# COMPUTE_CLUSTER0_SS_CFG register map
Vendor: Texas Instruments
Peripheral module from a debugger description file (folder J7VCL).
Registers are 32-bit, access per field, reset 0x0 unless marked. A register's access mark holds for its fields unless they carry their own. Offsets are as the file gives them; lines under a group give offsets from that group; [hi:lo] are bit positions; {n}, {i} and the like mark numbered series; 'fields as' and 'values as' point back to an identical list; <NAME> marks a mode.

## COMPUTE_CLUSTER0_SS_CFG
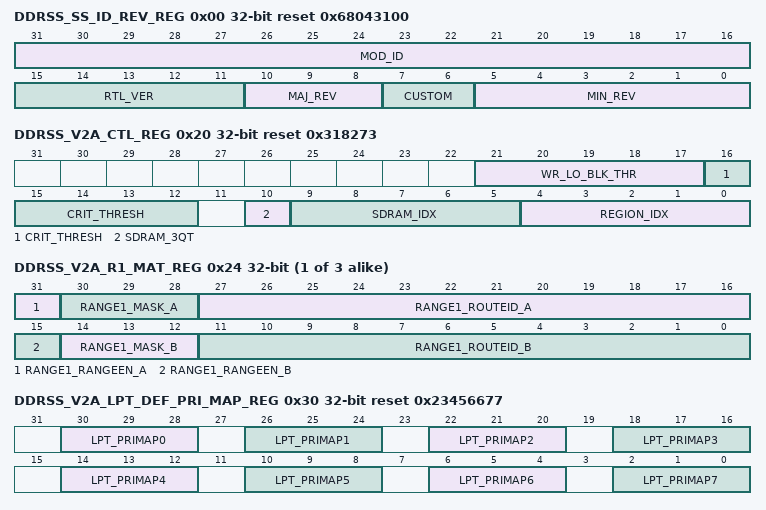
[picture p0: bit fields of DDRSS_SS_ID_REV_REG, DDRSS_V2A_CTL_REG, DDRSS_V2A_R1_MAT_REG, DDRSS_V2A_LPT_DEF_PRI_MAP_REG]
0x00 DDRSS_SS_ID_REV_REG ro reset 0x68043100 — Return to the . The Subsystem ID and Revision Register contains the module ID, major, and minor revisions for the subsystem.
  [31:16] MOD_ID — Module ID
  [15:11] RTL_VER — RTL version
  [10:8] MAJ_REV — Major revision
  [7:6] CUSTOM
  [5:0] MIN_REV — Minor revision
0x04 DDRSS_SS_CTL_REG — Return to the . The Subsystem Control Register contains fields for control functions required for submodules in the subsystem.
  [0] PHY_PLL_BYPASS rw — DDR PHY De-Skew PLL bypass.Write 1 to bypass PLL.
0x20 DDRSS_V2A_CTL_REG reset 0x318273 — Return to the . The MSMC2DDR Bridge Control register contains control functions required for the MSMC2DDR Bridge submodule.
  [21:17] WR_LO_BLK_THR rw — Write data threshold in 64 byte quantas.The MSMC2DDR bridge will block all Low Priority Thread writes to DDR when the total number of write data bytes sent to the DDR controller is greater than this value. The reset value of this field is optimal however, it can be changed for better traffic shaping.
  [16:12] CRIT_THRESH rw — Critical threshold.The MSMC2DDR bridge will block all Low Priority Thread traffic to DDR when the total number of commands sent to the DDR controller is greater than this value. The reset value of this field is optimal however, it can be changed for better traffic shaping.
  [10] SDRAM_3QT rw — Setting this field to a 1 will modify SDRAM Index to be 3/4 its programmed value to support 3, 6, 12 and 24 GB sizes.
  [9:5] SDRAM_IDX rw — SDRAM Index = log2(connected SDRAM size) - 16.The sdram_idx describes the number of address bits minus 16 that are used to determine the mask used to detect memory rollover and prevent aliasing and false coherency issues. Max size supported is 32GB. A programmed value greater than 0x13 will result in this field being reset to 0x13.
  [4:0] REGION_IDX rw — Region Index = log2(CBA region size) - 16.The region_idx describes the number of address bits minus 16 that are used to determine the mask used to detect memory rollover and prevent aliasing and false coherency issues. Max size supported is 32GB. A programmed value greater than 0x13 will result in this field being reset to 0x13.
{0x20+4i} DDRSS_V2A_R{i}_MAT_REG rw (i=1..3) — Return to the . The Range {i} Match Register allows a single master to a range of masters to change their priority mapping. This allows selective masters to be increased or decreased in effective priority. Range {i} Match Register uses the associated Range {i} Priority Map Register. The highest Range Match Register will take priority and will be used in case of multiple range matches.
  [31] RANGE{i}_RANGEEN_A — The range{i}_rangeen_a enables the RouteID AND'd with range{i}_mask_a to match the range{i}_routeid_a
  [30:28] RANGE{i}_MASK_A — The range{i}_mask_a allows a number of least significant bits to be ignored prior to the match of the routeid_a
  [27:16] RANGE{i}_ROUTEID_A — The range{i}_routeid_a is the value that is compared to the RouteID arriving on the command interface
  [15] RANGE{i}_RANGEEN_B — The range{i}_rangeen_b enables the RouteID AND'd with range{i}_mask_b to match the range{i}_routeid_b
  [14:12] RANGE{i}_MASK_B — The range{i}_mask_b allows a number of least significant bits to be ignored prior to the match of the routeid_b
  [11:0] RANGE{i}_ROUTEID_B — The range{i}_routeid_b is the value that is compared to the RouteID arriving on the command interface
0x30 DDRSS_V2A_LPT_DEF_PRI_MAP_REG reset 0x23456677 — Return to the . The LPT Default Priority Mapping Register is the default map for the inbound VBUSM.C priority on the Low Priority Thread to AXI priority.
  [30:28] LPT_PRIMAP0 rw — The field contains AXI priority value for VBUSM.C priority 0.0=highest priority. 7=lowest priority
  [26:24] LPT_PRIMAP1 rw — The field contains AXI priority value for VBUSM.C priority 1.0=highest priority. 7=lowest priority
  [22:20] LPT_PRIMAP2 rw — The field contains AXI priority value for VBUSM.C priority 2.0=highest priority. 7=lowest priority
  [18:16] LPT_PRIMAP3 rw — The field contains AXI priority value for VBUSM.C priority 3.0=highest priority. 7=lowest priority
  [14:12] LPT_PRIMAP4 rw — The field contains AXI priority value for VBUSM.C priority 4.0=highest priority. 7=lowest priority
  [10:8] LPT_PRIMAP5 rw — The field contains AXI priority value for VBUSM.C priority 5.0=highest priority. 7=lowest priority
  [6:4] LPT_PRIMAP6 rw — The field contains AXI priority value for VBUSM.C priority 6.0=highest priority. 7=lowest priority
  [2:0] LPT_PRIMAP7 rw — The field contains AXI priority value for VBUSM.C priority 7.0=highest priority. 7=lowest priority
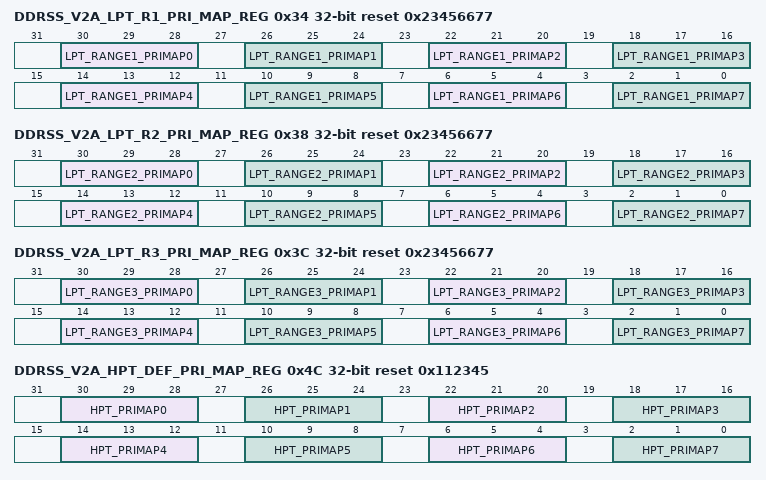
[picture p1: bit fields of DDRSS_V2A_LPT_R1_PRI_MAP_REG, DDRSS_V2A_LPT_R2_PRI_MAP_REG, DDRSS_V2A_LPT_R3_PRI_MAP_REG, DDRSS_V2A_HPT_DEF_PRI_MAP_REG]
0x34 DDRSS_V2A_LPT_R1_PRI_MAP_REG reset 0x23456677 — Return to the . The LPT Range 1 Priority Mapping Register is used to map the inbound VBUSM.C priority on the Low Priority Thread to AXI priority when a RouteID match 1 occurs. This allows the priority level to be changed from the LPT Default Priority Mapping value.
  [30-4n:28-4n] LPT_RANGE1_PRIMAP{n} rw (n=0..7) — The field contains AXI priority value for VBUSM.C priority {n} for range match 1.0=highest priority. 7=lowest priority
0x38 DDRSS_V2A_LPT_R2_PRI_MAP_REG reset 0x23456677 — Return to the . The LPT Range 2 Priority Mapping Register is used to map the inbound VBUSM.C priority on the Low Priority Thread to AXI priority when a RouteID match 2 occurs. This allows the priority level to be changed from the LPT Default Priority Mapping value.
  [30-4n:28-4n] LPT_RANGE2_PRIMAP{n} rw (n=0..7) — The field contains AXI priority value for VBUSM.C priority {n} for range match 2.0=highest priority. 7=lowest priority
0x3C DDRSS_V2A_LPT_R3_PRI_MAP_REG reset 0x23456677 — Return to the . The LPT Range 3 Priority Mapping Register is used to map the inbound VBUSM.C priority on the Low Priority Thread to AXI priority when a RouteID match 3 occurs. This allows the priority level to be changed from the LPT Default Priority Mapping value.
  [30-4n:28-4n] LPT_RANGE3_PRIMAP{n} rw (n=0..7) — The field contains AXI priority value for VBUSM.C priority {n} for range match 3.0=highest priority. 7=lowest priority
0x4C DDRSS_V2A_HPT_DEF_PRI_MAP_REG reset 0x112345 — Return to the . The HPT Default Priority Mapping Register is the default map for the inbound VBUSM.C priority on the High Priority Thread to the AXI priority.
  [30:28] HPT_PRIMAP0 rw — The field contains AXI priority value for VBUSM.C priority 0.0=highest priority. 7=lowest priority
  [26:24] HPT_PRIMAP1 rw — The field contains AXI priority value for VBUSM.C priority 1.0=highest priority. 7=lowest priority
  [22:20] HPT_PRIMAP2 rw — The field contains AXI priority value for VBUSM.C priority 2.0=highest priority. 7=lowest priority
  [18:16] HPT_PRIMAP3 rw — The field contains AXI priority value for VBUSM.C priority 3.0=highest priority. 7=lowest priority
  [14:12] HPT_PRIMAP4 rw — The field contains AXI priority value for VBUSM.C priority 4.0=highest priority. 7=lowest priority
  [10:8] HPT_PRIMAP5 rw — The field contains AXI priority value for VBUSM.C priority 5.0=highest priority. 7=lowest priority
  [6:4] HPT_PRIMAP6 rw — The field contains AXI priority value for VBUSM.C priority 6.0=highest priority. 7=lowest priority
  [2:0] HPT_PRIMAP7 rw — The field contains AXI priority value for VBUSM.C priority 7.0=highest priority. 7=lowest priority
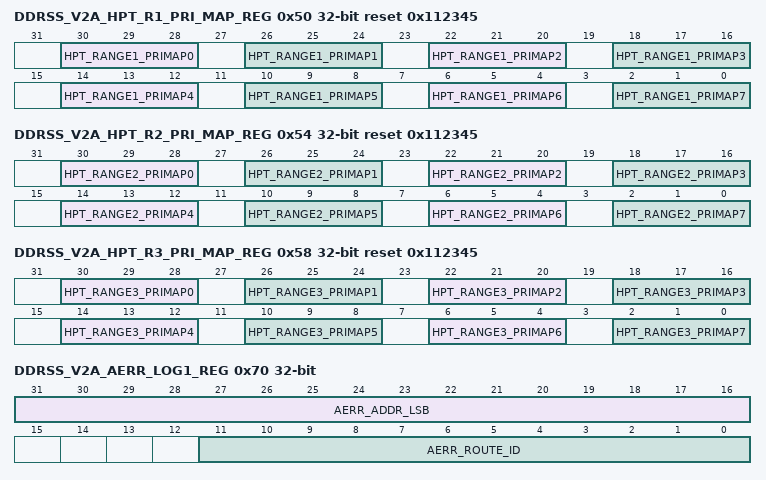
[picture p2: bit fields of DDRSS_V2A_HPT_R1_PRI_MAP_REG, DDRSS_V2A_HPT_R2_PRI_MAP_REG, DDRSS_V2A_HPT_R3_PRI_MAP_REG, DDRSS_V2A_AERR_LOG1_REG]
0x50 DDRSS_V2A_HPT_R1_PRI_MAP_REG reset 0x112345 — Return to the . The HPT Range 1 Priority Mapping Register is used to map the inbound VBUSM.C priority on the High Priority Thread to AXI priority when a RouteID match 1 occurs. This allows the priority level to be changed from the HPT Default Priority Mapping value.
  [30-4n:28-4n] HPT_RANGE1_PRIMAP{n} rw (n=0..7) — The field contains AXI priority value for VBUSM.C priority {n} for range match 1.0=highest priority. 7=lowest priority
0x54 DDRSS_V2A_HPT_R2_PRI_MAP_REG reset 0x112345 — Return to the . The HPT Range 2 Priority Mapping Register is used to map the inbound VBUSM.C priority on the High Priority Thread to AXI priority when a RouteID match 2 occurs. This allows the priority level to be changed from the HPT Default Priority Mapping value.
  [30-4n:28-4n] HPT_RANGE2_PRIMAP{n} rw (n=0..7) — The field contains AXI priority value for VBUSM.C priority {n} for range match 2.0=highest priority. 7=lowest priority
0x58 DDRSS_V2A_HPT_R3_PRI_MAP_REG reset 0x112345 — Return to the . The HPT Range 3 Priority Mapping Register is used to map the inbound VBUSM.C priority on the High Priority Thread to AXI priority when a RouteID match 3 occurs. This allows the priority level to be changed from the HPT Default Priority Mapping value.
  [30-4n:28-4n] HPT_RANGE3_PRIMAP{n} rw (n=0..7) — The field contains AXI priority value for VBUSM.C priority {n} for range match 3.0=highest priority. 7=lowest priority
0x70 DDRSS_V2A_AERR_LOG1_REG access not given — Return to the . The Address Error Log 1 register displays the RouteID and lsb of the address for the first VBUSM.C command that was outside the programmed addressing range. Writing a 0x1 will clear all fields. Writing any other value has no effect. The Address Error Log 2 register will also be cleared upon writing this register.
  [31:16] AERR_ADDR_LSB — Address[15:0] of the VBUSM.C command (access RW1C)
  [11:0] AERR_ROUTE_ID — RouteID of the VBUSM.C write command (access RW1C)
0x74 DDRSS_V2A_AERR_LOG2_REG ro — Return to the . The Address Error Log 2 registers displays the msb of the address for the first VBUSM.C command that was outside the programmed addressing range. This register will be cleared upon writing the Address Error Log 1 register.
  [31:0] AERR_ADDR_MSB — Address[34:16] of the VBUSM.C command
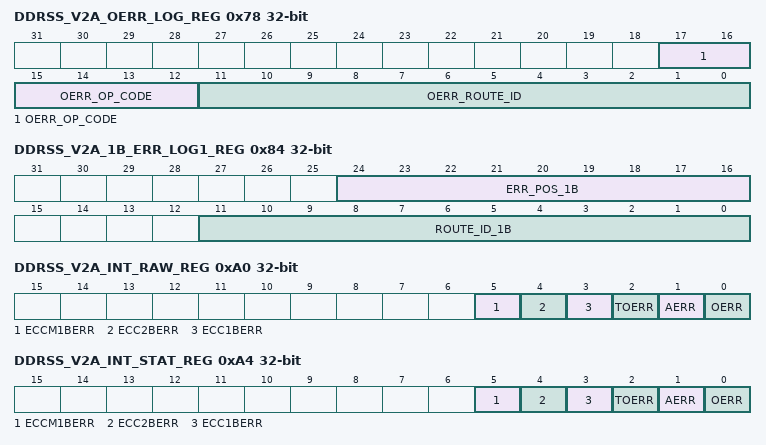
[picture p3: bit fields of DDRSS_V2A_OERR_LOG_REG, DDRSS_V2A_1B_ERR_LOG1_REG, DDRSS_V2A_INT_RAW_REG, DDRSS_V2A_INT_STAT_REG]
0x78 DDRSS_V2A_OERR_LOG_REG access not given — Return to the . The Opcode Error Log register displays the RouteID and opcode for the first VBUSM.C command that had an unsupported opcode. Writing a 0x1 will clear all fields. Writing any other value has no effect.
  [17:12] OERR_OP_CODE — Opcode of the VBUSM.C command (access RW1C)
  [11:0] OERR_ROUTE_ID — RouteID of the VBUSM.C command (access RW1C)
0x80 DDRSS_V2A_1B_ERR_CNT_REG access not given — Return to the . MSMC2DDR Bridge 1-Bit EDC Error Count Register
  [15:0] EDC_1B_ERR_CNT — 16-bit counter that displays number of 1-bit EDC errors on write data received on the VBUSM.C interface. Writing a 0x1 will clear this count. Writing any other value has no effect. (access RW1C)
0x84 DDRSS_V2A_1B_ERR_LOG1_REG access not given — Return to the . The 1-Bit EDC Error Log 1 register displays the RouteID and error position of the first VBUSM.C write that incurred 1-bit EDC error. Writing a 0x1 will clear all fields. Writing any other value has no effect. The 1-Bit EDC Error Log 2 register will also be cleared upon writing this register.
  [24:16] ERR_POS_1B — Bit error position (access RW1C)
  [11:0] ROUTE_ID_1B — RouteID of the VBUSM.C write command (access RW1C)
0x88 DDRSS_V2A_1B_ERR_LOG2_REG ro — Return to the . The 1-Bit EDC Error Log 2 registers displays the address of the first VBUSM.C write that incurred 1-bit EDC error. This register will be cleared upon writing the 1-Bit EDC Error Log 1 register.
  [29:0] ADDR_MSB_1B — Address[34:5] of the VBUSM.C write command
0x8C DDRSS_V2A_2B_ERR_LOG1_REG access not given — Return to the . The 2-Bit EDC Error Log 1 register displays the RouteID of the first VBUSM.C write that incurred 2-bit EDC error. Writing a 0x1 clear all fields. Writing any other value has no effect. The 2-Bit EDC Error Log 2 register will also be cleared upon writing this register.
  [11:0] ROUTE_ID_2B — RouteID of the VBUSM.C write command (access RW1C)
0x90 DDRSS_V2A_2B_ERR_LOG2_REG ro — Return to the . The 2-Bit EDC Error Log 1 register displays the address of the first VBUSM.C write that incurred 2-bit EDC error. This register will be cleared upon writing the 2-Bit EDC Error Log 1 register.
  [29:0] ADR_MSB_2B — Address[34:5] of the VBUSM.C write command
0x9C DDRSS_V2A_BUS_TO reset 0xFFFFFF — Return to the . MSMC2DDR Bridge Bus Timeout Register
  [23:0] BUS_TIMER rw — AXI bus timeout value.Number of DDR clock cycles after which the MSMC2DDR bridge times out if a hang on the controller AXI interface is detected. A value of N will be equal to N x 16 clocks. Writing a 0 will disable the timeout feature.
0xA0 DDRSS_V2A_INT_RAW_REG access not given — Return to the . MSMC2DDR Bridge Interrupt Raw Status Register
  [5] ECCM1BERR — Raw status of SDRAM ECC multi 1-bit errors in same SDRAM burst.Write 1 to set the (raw) status, mostly for debug. Writing a 0 has no effect. (access RW1S)
  [4] ECC2BERR — Raw status of SDRAM ECC 2-bit error.Write 1 to set the (raw) status, mostly for debug. Writing a 0 has no effect. (access RW1S)
  [3] ECC1BERR — Raw status of SDRAM ECC 1-bit error.Write 1 to set the (raw) status, mostly for debug. Writing a 0 has no effect. (access RW1S)
  [2] TOERR — Raw status of MSMC2DDR Bridge interrupt for controller AXI interface timeout.Write 1 to set the (raw) status, mostly for debug. Writing a 0 has no effect. (access RW1S)
  [1] AERR — Raw status of MSMC2DDR Bridge interrupt for VBUSM.C address outside the programmed range.Write 1 to set the (raw) status, mostly for debug. Writing a 0 has no effect. (access RW1S)
  [0] OERR — Raw status of MSMC2DDR Bridge interrupt for VBUSM.C unsupported opcode.Write 1 to set the (raw) status, mostly for debug. Writing a 0 has no effect. (access RW1S)
0xA4 DDRSS_V2A_INT_STAT_REG access not given — Return to the . MSMC2DDR Bridge Interrupt Status Register
  [5] ECCM1BERR — Enabled status of SDRAM ECC multi 1-bit errors in same SDRAM burst.Write 1 to clear the status after interrupt has been serviced (raw status gets cleared, i.e. even if not enabled). Writing a 0 has no effect. (access RW1C)
  [4] ECC2BERR — Enabled status of SDRAM ECC 2-bit error.Write 1 to clear the status after interrupt has been serviced (raw status gets cleared, i.e. even if not enabled). Writing a 0 has no effect. (access RW1C)
  [3] ECC1BERR — Enabled status of SDRAM ECC 1-bit error.Write 1 to clear the status after interrupt has been serviced (raw status gets cleared, i.e. even if not enabled). Writing a 0 has no effect. (access RW1C)
  [2] TOERR — Enabled status of MSMC2DDR Bridge interrupt for controller AXI interface timeout.Write 1 to clear the status after interrupt has been serviced (raw status gets cleared, i.e. even if not enabled). Writing a 0 has no effect. (access RW1C)
  [1] AERR — Enabled status of MSMC2DDR Bridge interrupt for VBUSM.C address outside the programmed range.Write 1 to clear the status after interrupt has been serviced (raw status gets cleared, i.e. even if not enabled). Writing a 0 has no effect. (access RW1C)
  [0] OERR — Enabled status of MSMC2DDR Bridge interrupt for VBUSM.C unsupported opcode.Write 1 to clear the status after interrupt has been serviced (raw status gets cleared, i.e. even if not enabled). Writing a 0 has no effect. (access RW1C)
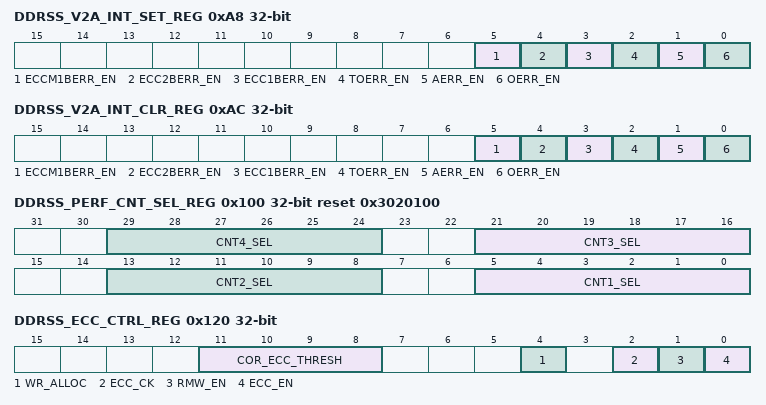
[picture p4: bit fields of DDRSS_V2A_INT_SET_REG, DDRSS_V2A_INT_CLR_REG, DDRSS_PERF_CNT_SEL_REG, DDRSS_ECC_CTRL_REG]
0xA8 DDRSS_V2A_INT_SET_REG access not given — Return to the . MSMC2DDR Bridge Interrupt Enable Set Register
  [5] ECCM1BERR_EN — Enable set for SDRAM ECC multi1-bit errors in same SDRAM burst. Writing a 1 will enable the interrupt, and set this bit as well as the corresponding Interrupt Enable Clear Register. Writing a 0 has no effect. (access RW1S)
  [4] ECC2BERR_EN — Enable set for SDRAM ECC2-bit error. Writing a 1 will enable the interrupt, and set this bit as well as the corresponding Interrupt Enable Clear Register. Writing a 0 has no effect. (access RW1S)
  [3] ECC1BERR_EN — Enable set for SDRAM ECC1-bit error. Writing a 1 will enable the interrupt, and set this bit as well as the corresponding Interrupt Enable Clear Register. Writing a 0 has no effect. (access RW1S)
  [2] TOERR_EN — Enable set for MSMC2DDR Bridge interrupt for controller AXI interface timeout.Writing a 1 will enable the interrupt, and set this bit as well as the corresponding Interrupt Enable Clear Register. Writing a 0 has no effect. (access RW1S)
  [1] AERR_EN — Enable set for MSMC2DDR Bridge interrupt for VBUSM.C address outside the programmed range.Writing a 1 will enable the interrupt, and set this bit as well as the corresponding Interrupt Enable Clear Register. Writing a 0 has no effect. (access RW1S)
  [0] OERR_EN — Enable set for MSMC2DDR Bridge interrupt for VBUSM.C unsupported opcode.Writing a 1 will enable the interrupt, and set this bit as well as the corresponding Interrupt Enable Clear Register. Writing a 0 has no effect. (access RW1S)
0xAC DDRSS_V2A_INT_CLR_REG access not given — Return to the . MSMC2DDR Bridge Interrupt Enable Clear Register
  [5] ECCM1BERR_EN — Enable clear for SDRAM ECC multi1-bit errors in same SDRAM burst. Writing a 1 will disable the interrupt, and clear this bit as well as the corresponding Interrupt Enable Set Register. Writing a 0 has no effect. (access RW1C)
  [4] ECC2BERR_EN — Enable clear for SDRAM ECC2-bit error. Writing a 1 will disable the interrupt, and clear this bit as well as the corresponding Interrupt Enable Set Register. Writing a 0 has no effect. (access RW1C)
  [3] ECC1BERR_EN — Enable clear for SDRAM ECC1-bit error. Writing a 1 will disable the interrupt, and clear this bit as well as the corresponding Interrupt Enable Set Register. Writing a 0 has no effect. (access RW1C)
  [2] TOERR_EN — Enable clear for MSMC2DDR Bridge interrupt for controller AXI interface timeout.Writing a 1 will disable the interrupt, and clear this bit as well as the corresponding Interrupt Enable Set Register. Writing a 0 has no effect. (access RW1C)
  [1] AERR_EN — Enable clear for MSMC2DDR Bridge interrupt for VBUSM.C address outside the programmed range.Writing a 1 will disable the interrupt, and clear this bit as well as the corresponding Interrupt Enable Set Register. Writing a 0 has no effect. (access RW1C)
  [0] OERR_EN — Enable clear for MSMC2DDR Bridge interrupt for VBUSM.C unsupported opcode.Writing a 1 will disable the interrupt, and clear this bit as well as the corresponding Interrupt Enable Set Register. Writing a 0 has no effect. (access RW1C)
0xB0 DDRSS_V2A_EOI_REG — Return to the . MSMC2DDR Bridge End of Interrupt Register
  [1:0] EOI wo — Software End Of Interrupt (EOI) control.Write 0 for aerr/oerr/toerr interrupt. Write 1 for ecc1b interrupt. Write 2 for ecc2b interrupt. This field always reads 0 (no EOI memory).
0x100 DDRSS_PERF_CNT_SEL_REG reset 0x3020100 — Return to the . The Performance Counter Select register is used to select the statistic type to be counted in the corresponding Performance Counter register.
  [8n-3:8n-8] CNT{n}_SEL rw (n=1..4) — Statistic select for Performance Counter {n} register. 0x0 = Counts every Write command. 0x1 = Counts every Read command. 0x2 = Counts every read as a result of a RMW command. 0x3 = Counts every Activate command. 0x4 = Counts every Precharge command. 0x5 = Counts every Precharge All command. 0x6 = Counts every Mode Register Read command. 0x7 = Counts every Mode Register Write command. 0x8 = Counts every Per Bank Refresh command. 0x9 = Counts every Auto Refresh command. 0xA = Counts every ZQ Calib Long command. 0xB = Counts every ZQ Calib Short command. 0xC = Counts every Write-to-Read and Read-to-Write bus-turn-around. 0xD = Counts every Write-to-Write address collision. 0xE = Counts every Write-to-Read address collision. 0xF = Counts every Read-to-Write address collision. 0x10 = Counts every Read-to-Read address collision. 0x11 = Counts every exit from Power-Down Self-Refresh mode. 0x12 = Counts every entry into Power-Down Self-Refresh mode. 0x13 = Counts every cycle for which the DDR Controller stays in Power-Down Self-Refresh mode. 0x14 = Counts every exit from Power-Down mode. 0x15 = Counts every entry into Power-Down mode. 0x16 = Counts every cycle for which the DDR Controller stays in Power-Down mode. 0x17 = Counts every exit from Self-Refresh mode. 0x18 = Counts every entry into Self-Refresh mode. 0x19 = Counts every cycle for which the DDR Controller stays in Self-Refresh mode. 0x1A = Reserved 0x1B = Reserved 0x1C = Counts every cycle for which the DDR Controller command queue is full. 0x1D = Counts every cycle for which the DDR Controller info FIFO is full. 0x1E = Counts every cycle for which the DDR Controller write latency FIFO is full. 0x1F = Counts every cycle for which the DDR Controller port command FIFO is full. 0x20 = Counts every cycle for which the DDR Controller write response FIFO is full. 0x21 = Counts every cycle for which the DDR Controller port write FIFO is full. 0x22 = Counts every cycle for which the DDR Controller core read FIFO is full. 0x23 = Counts every cycle for which the DDR Controller port read FIFO is full. 0x24-0x2F = Reserved
{0x100+4i} DDRSS_PERF_CNT{i}_REG ro (i=1..4) — Return to the . Performance Counter {i} Register
  [31:0] CNT{i} — Soft 32-bit counter that can be configured as specified in the Performance Counter Select Register.
0x120 DDRSS_ECC_CTRL_REG — Return to the . ECC Control Register
  [11:8] COR_ECC_THRESH rw — Threshold for1-bit ECC errors in multiple data words in an SDRAM burst that create an uncorrected error fault indication. Value of 0/1 means 2 or more 1-bit errors in multiple data words will result in an uncorrected error fault indication, value of 2 means 3 or more 1-bit errors will result in an uncorrected error fault indication, and so on. Value of 8 or greater disables this feature. This field must always be kept at default, and only changed for debug.
  [4] WR_ALLOC rw — When set to 1, an unassigned ECC cache-line will be allocated for a write with routeID that do not match any of the mapped routeID's.
  [2] ECC_CK rw — Set 1 to enable ECC verification for read accesses when ecc_en=1.The value of this field is ignored when ecc_en=0. This bit must be set and kept static before using DDR.
  [1] RMW_EN rw — Read modify write enable.Set 1 to enable RMW functionality for sub-quanta accesses when ecc_en=1. This bit must be set to 1 if ecc_en is set to a 1 to ensure subquanta accesses to DRAM do not result in ECC errors. This bit must be set and kept static before using DDR.
  [0] ECC_EN rw — DRAM ECC enable.Setting a 1 causes ECC to be written to DRAM. This bit must be set and kept static before using DDR.
0x124 DDRSS_ECC_RID_INDX_REG — Return to the . ECC Cache RouteID Index Register
  [5:0] ECCRID_ADR rw — This index specifies the ECC cache entry number that the eccrid_val is mapped to.
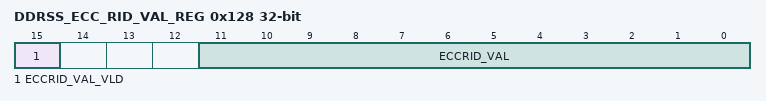
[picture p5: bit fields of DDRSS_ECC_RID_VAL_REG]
0x128 DDRSS_ECC_RID_VAL_REG — Return to the . ECC Cache RouteID Write Value Register
  [15] ECCRID_VAL_VLD rw — A 1 in this field indicates that value in eccrid_val is valid.
  [11:0] ECCRID_VAL rw — RouteID value written or read.
{0x130+8i} DDRSS_ECC_R{i}_STR_ADDR_REG reset 0x7FFFF (i=0..2) — Return to the . ECC Range {i} Start Address Register
  [18:0] ECC_STR_ADR_{i} rw — Start caddress[34:16] for ECC range {i}. Setting the start address greater than the end address disables the range. The range is inclusive of the start and end addresses. This field must be set and kept static before using DDR.
{0x134+8i} DDRSS_ECC_R{i}_END_ADDR_REG (i=0..2) — Return to the . ECC Range {i} End Address Register
  [18:0] ECC_END_ADR_{i} rw — End caddress[34:16] for ECC range {i}. Setting the start address greater than the end address disables the range. The range is inclusive of the start and end addresses. This field must be set and kept static before using DDR.
0x150 DDRSS_ECC_1B_ERR_CNT_REG access not given — Return to the . ECC 1-Bit Error Count Register
  [15:0] ECC_1B_ERR_CNT — 16-bit counter that displays number of 1-bit ECC errors on SDRAM data. Writing a 0x1 will clear this count. Writing any other value has no effect. (access RW1C)
0x154 DDRSS_ECC_1B_ERR_THRSH_REG — Return to the . ECC 1-Bit Error Threshold Register
  [15:0] ECC_1B_ERR_THRSH rw — ECC1-bit error threshold. The bridge will generate an interrupt when the ECC 1-bit error count is equal to or greater than this threshold. A value of 0 will disable the generation of interrupt.
0x158 DDRSS_ECC_1B_ERR_ADR_LOG_REG access not given — Return to the . ECC 1-Bit Error Address Log Register
  [29:0] ECC_1B_ERR_ADR — ECC1-bit error address. 32-byte aligned address that had the 1-bit ECC error. This field displays the first address logged in the 2 deep logging FIFO. Writing a 0x1 will pop the top element of the FIFO. Writing any other value has no effect. (access RW1C)
0x15C DDRSS_ECC_1B_ERR_MSK_LOG_REG ro — Return to the . ECC 1-Bit Error Mask Log Register
  [7:0] ECC_1B_ERR_MSK — ECC1-bit error mask. Mask for the 64-byte data block that had the 1-bit ECC errors. Each bit represents an ECC quanta (8 bytes) in the 64-byte data block starting at address specified by ecc_1b_err_adr. Value of 1 on the bit represents an error in that particular 8 bytes. This field displays the first mask logged in the 2 deep logging FIFO along with the ecc_1b_err_adr. The same mechanism used to pop ecc_1b_err_adr is used to pop this field.
0x160 DDRSS_ECC_2B_ERR_ADR_LOG_REG access not given — Return to the . ECC 2-Bit Error Address Log Register
  [29:0] ECC_2B_ERR_ADR — ECC2-bit error address. 32-byte aligned address that had the 2-bit ECC error. Writing a 0x1 will clear this field and the ecc_2b_err_msk field. Writing any other value has no effect. (access RW1C)
0x164 DDRSS_ECC_2B_ERR_MSK_LOG_REG ro — Return to the . ECC 2-Bit Error Mask Log Register
  [7:0] ECC_2B_ERR_MSK — ECC2-bit error mask. Mask for the 64-byte data block that had the 2-bit ECC errors. Each bit represents an ECC quanta (8 bytes) in the 64-byte data block starting at address specified by ecc_2b_err_adr. Value of 1 on the bit represents an error in that particular 8 bytes.
0x180 DDRSS_PHY_BIST_CTRL_REG — Return to the . PHY BIST Control Register
  [15:0] BIST_TSEL_SELECT rw — This field controls the bist_tsel_select input of the PHY.For details please refer to the PHY specification.
